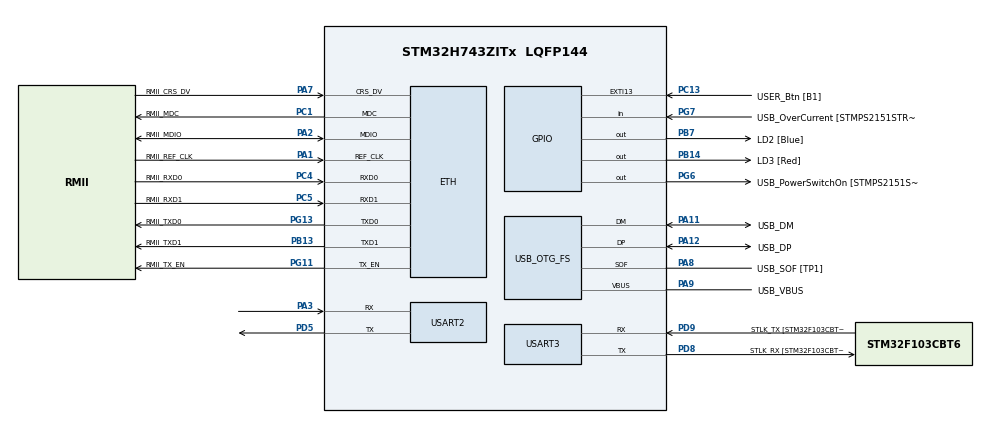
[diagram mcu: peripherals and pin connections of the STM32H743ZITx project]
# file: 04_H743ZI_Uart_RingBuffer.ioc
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ETH.MediaInterface=HAL_ETH_RMII_MODE
Mcu.Family=STM32H7
Mcu.Name=STM32H743ZITx
Mcu.Package=LQFP144
NVIC.PriorityGroup=NVIC_PRIORITYGROUP_4
NVIC.USART2_IRQn=true\:0\:0\:false\:false\:true\:true
PA1.GPIO_Label=RMII_REF_CLK
PA1.Mode=RMII
PA1.Signal=ETH_REF_CLK
PA10.GPIO_Label=USB_ID
PA10.Signal=USB_OTG_FS_ID
PA11.GPIO_Label=USB_DM
PA11.Mode=Device_Only
PA11.Signal=USB_OTG_FS_DM
PA12.GPIO_Label=USB_DP
PA12.Mode=Device_Only
PA12.Signal=USB_OTG_FS_DP
PA13\ (JTMS/SWDIO).GPIO_Label=TMS
PA13\ (JTMS/SWDIO).Mode=Serial_Wire
PA13\ (JTMS/SWDIO).Signal=SYS_JTMS-SWDIO
PA14\ (JTCK/SWCLK).GPIO_Label=TCK
PA14\ (JTCK/SWCLK).Mode=Serial_Wire
PA14\ (JTCK/SWCLK).Signal=SYS_JTCK-SWCLK
PA2.GPIO_Label=RMII_MDIO
PA2.Mode=RMII
PA2.Signal=ETH_MDIO
PA3.Mode=Asynchronous
PA3.Signal=USART2_RX
PA7.GPIO_Label=RMII_CRS_DV
PA7.Mode=RMII
PA7.Signal=ETH_CRS_DV
PA8.GPIO_Label=USB_SOF [TP1]
PA8.Mode=Activate_SOF_FS
PA8.Signal=USB_OTG_FS_SOF
PA9.GPIO_Label=USB_VBUS
PA9.Mode=Activate_VBUS
PA9.Signal=USB_OTG_FS_VBUS
PB13.GPIO_Label=RMII_TXD1
PB13.Mode=RMII
PB13.Signal=ETH_TXD1
PB14.GPIO_Label=LD3 [Red]
PB14.Signal=GPIO_Output
PB3\ (JTDO/TRACESWO).GPIO_Label=SWO
PB3\ (JTDO/TRACESWO).Signal=SYS_JTDO-SWO
PB7.GPIO_Label=LD2 [Blue]
PB7.Signal=GPIO_Output
PC1.GPIO_Label=RMII_MDC
PC1.Mode=RMII
PC1.Signal=ETH_MDC
PC13.GPIO_Label=USER_Btn [B1]
PC13.Signal=GPXTI13
PC14-OSC32_IN\ (OSC32_IN).Mode=LSE-External-Oscillator
PC14-OSC32_IN\ (OSC32_IN).Signal=RCC_OSC32_IN
PC15-OSC32_OUT\ (OSC32_OUT).Mode=LSE-External-Oscillator
PC15-OSC32_OUT\ (OSC32_OUT).Signal=RCC_OSC32_OUT
PC4.GPIO_Label=RMII_RXD0
PC4.Mode=RMII
PC4.Signal=ETH_RXD0
PC5.GPIO_Label=RMII_RXD1
PC5.Mode=RMII
PC5.Signal=ETH_RXD1
PD5.Mode=Asynchronous
PD5.Signal=USART2_TX
PD8.GPIO_Label=STLK_RX [STM32F103CBT6_PA3]
PD8.Mode=Asynchronous
PD8.Signal=USART3_TX
PD9.GPIO_Label=STLK_TX [STM32F103CBT6_PA2]
PD9.Mode=Asynchronous
PD9.Signal=USART3_RX
PG11.GPIO_Label=RMII_TX_EN
PG11.Mode=RMII
PG11.Signal=ETH_TX_EN
PG13.GPIO_Label=RMII_TXD0
PG13.Mode=RMII
PG13.Signal=ETH_TXD0
PG6.GPIO_Label=USB_PowerSwitchOn [STMPS2151STR_EN]
PG6.Signal=GPIO_Output
PG7.GPIO_Label=USB_OverCurrent [STMPS2151STR_FAULT]
PG7.Signal=GPIO_Input
PH0-OSC_IN\ (PH0).GPIO_Label=MCO
PH0-OSC_IN\ (PH0).Mode=HSE-External-Clock-Source
PH0-OSC_IN\ (PH0).Signal=RCC_OSC_IN
PH1-OSC_OUT\ (PH1).Mode=HSE-External-Clock-Source
PH1-OSC_OUT\ (PH1).Signal=RCC_OSC_OUT
ProjectManager.HeapSize=0x200
ProjectManager.StackSize=0x400
ProjectManager.TargetToolchain=EWARM V8
RCC.48MHZClocksFreq_Value=24000000
RCC.ADCFreq_Value=16125000
RCC.AHBFreq_Value=216000000
RCC.APB1CLKDivider=RCC_HCLK_DIV4
RCC.APB1Freq_Value=100000000
RCC.APB1TimFreq_Value=108000000
RCC.APB2CLKDivider=RCC_HCLK_DIV2
RCC.APB2Freq_Value=100000000
RCC.APB2TimFreq_Value=216000000
RCC.APB3Freq_Value=100000000
RCC.APB4Freq_Value=100000000
RCC.CortexFreq_Value=400000000
RCC.D1PPRE=RCC_APB3_DIV2
RCC.D2PPRE1=RCC_APB1_DIV2
RCC.D2PPRE2=RCC_APB2_DIV2
RCC.D3PPRE=RCC_APB4_DIV2
RCC.DIVM1=1
RCC.DIVN1=100
RCC.DIVQ1=4
RCC.HCLKFreq_Value=200000000
RCC.HPRE=RCC_HCLK_DIV2
RCC.HSE_VALUE=8000000
RCC.HSI_VALUE=64000000
RCC.PLLM=25
RCC.PLLMUL=RCC_PLL_MUL9
RCC.PLLN=432
RCC.PLLQ=9
RCC.PLLSourceVirtual=RCC_PLLSOURCE_HSE
RCC.PRESCALERUSB=RCC_USBCLKSOURCE_PLL_DIV1_5
RCC.SYSCLKFreq_VALUE=400000000
RCC.SYSCLKSource=RCC_SYSCLKSOURCE_PLLCLK
RCC.SYSCLKSourceVirtual=RCC_SYSCLKSOURCE_PLLCLK
RCC.USBCLockSelection=RCC_USBCLKSOURCE_HSI48
RCC.USBFreq_Value=48000000
RCC.VCOOutputFreq_Value=432000000
USART2.VirtualMode-Asynchronous=VM_ASYNC
USART3.VirtualMode-Asynchronous=VM_ASYNC
USB_OTG_FS.VirtualMode=Device_Only
board=NUCLEO-H743ZI

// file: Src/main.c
/* USER CODE BEGIN Header */
/**
  ******************************************************************************
  * @file           : main.c
  * @brief          : Main program body
  ******************************************************************************
  ** This notice applies to any and all portions of this file
  * that are not between comment pairs USER CODE BEGIN and
  * USER CODE END. Other portions of this file, whether
  * inserted by the user or by software development tools
  * are owned by their respective copyright owners.
  *
  * COPYRIGHT(c) 2019 STMicroelectronics
  *
  * Redistribution and use in source and binary forms, with or without modification,
  * are permitted provided that the following conditions are met:
  *   1. Redistributions of source code must retain the above copyright notice,
  *      this list of conditions and the following disclaimer.
  *   2. Redistributions in binary form must reproduce the above copyright notice,
  *      this list of conditions and the following disclaimer in the documentation
  *      and/or other materials provided with the distribution.
  *   3. Neither the name of STMicroelectronics nor the names of its contributors
  *      may be used to endorse or promote products derived from this software
  *      without specific prior written permission.
  *
  * THIS SOFTWARE IS PROVIDED BY THE COPYRIGHT HOLDERS AND CONTRIBUTORS "AS IS"
  * AND ANY EXPRESS OR IMPLIED WARRANTIES, INCLUDING, BUT NOT LIMITED TO, THE
  * IMPLIED WARRANTIES OF MERCHANTABILITY AND FITNESS FOR A PARTICULAR PURPOSE ARE
  * DISCLAIMED. IN NO EVENT SHALL THE COPYRIGHT HOLDER OR CONTRIBUTORS BE LIABLE
  * FOR ANY DIRECT, INDIRECT, INCIDENTAL, SPECIAL, EXEMPLARY, OR CONSEQUENTIAL
  * DAMAGES (INCLUDING, BUT NOT LIMITED TO, PROCUREMENT OF SUBSTITUTE GOODS OR
  * SERVICES; LOSS OF USE, DATA, OR PROFITS; OR BUSINESS INTERRUPTION) HOWEVER
  * CAUSED AND ON ANY THEORY OF LIABILITY, WHETHER IN CONTRACT, STRICT LIABILITY,
  * OR TORT (INCLUDING NEGLIGENCE OR OTHERWISE) ARISING IN ANY WAY OUT OF THE USE
  * OF THIS SOFTWARE, EVEN IF ADVISED OF THE POSSIBILITY OF SUCH DAMAGE.
  *
  ******************************************************************************
  */
/* USER CODE END Header */

#include "main.h"
#include "eth.h"
#include "usart.h"
#include "usb_otg.h"
#include "gpio.h"

void SystemClock_Config(void);

int main(void)
{

  /* MCU Configuration--------------------------------------------------------*/

  /* Reset of all peripherals, Initializes the Flash interface and the Systick. */
  HAL_Init();

  /* Configure the system clock */
  SystemClock_Config();

  /* Initialize all configured peripherals */
  MX_GPIO_Init();
  MX_ETH_Init();
  MX_USART3_UART_Init();
  MX_USB_OTG_FS_PCD_Init();
  MX_USART2_UART_Init();

  /* USER CODE BEGIN 2 */
	uart_hal_buffer_init();
	setvbuf( stdout, NULL, _IONBF, 0 );
	printf( "\n\rSTM32F401RE HAL_UART TEST!\n\r" );
	HAL_UART_Receive_IT( &huart2, &uart_hal_rx.dummy, 1 );
  /* USER CODE END 2 */

  /* Infinite loop */
  /* USER CODE BEGIN WHILE */
  uint32_t	tickstart = HAL_GetTick();
  uint32_t	ticknow;
  uint32_t	t = 0;
  while (1)
  {
  	ticknow	= HAL_GetTick();
  	if( ( ticknow - tickstart ) > 100 )
  	{
  		tickstart = ticknow;
  		printf( "Count : %lu \n\r", t++ );
  	}

  	uart_hal_rx_monitor();
    /* USER CODE END WHILE */

  }
}

void SystemClock_Config(void)
{
  RCC_OscInitTypeDef RCC_OscInitStruct = {0};
  RCC_ClkInitTypeDef RCC_ClkInitStruct = {0};
  RCC_PeriphCLKInitTypeDef PeriphClkInitStruct = {0};

  /**Supply configuration update enable
  */
  MODIFY_REG(PWR->CR3, PWR_CR3_SCUEN, 0);
  /**Configure the main internal regulator output voltage
  */
  __HAL_PWR_VOLTAGESCALING_CONFIG(PWR_REGULATOR_VOLTAGE_SCALE1);

  while ((PWR->D3CR & (PWR_D3CR_VOSRDY)) != PWR_D3CR_VOSRDY)
  {

  }
  /**Initializes the CPU, AHB and APB busses clocks
  */
  RCC_OscInitStruct.OscillatorType = RCC_OSCILLATORTYPE_HSI48|RCC_OSCILLATORTYPE_HSE;
  RCC_OscInitStruct.HSEState = RCC_HSE_BYPASS;
  RCC_OscInitStruct.HSI48State = RCC_HSI48_ON;
  RCC_OscInitStruct.PLL.PLLState = RCC_PLL_ON;
  RCC_OscInitStruct.PLL.PLLSource = RCC_PLLSOURCE_HSE;
  RCC_OscInitStruct.PLL.PLLM = 1;
  RCC_OscInitStruct.PLL.PLLN = 100;
  RCC_OscInitStruct.PLL.PLLP = 2;
  RCC_OscInitStruct.PLL.PLLQ = 4;
  RCC_OscInitStruct.PLL.PLLR = 2;
  RCC_OscInitStruct.PLL.PLLRGE = RCC_PLL1VCIRANGE_3;
  RCC_OscInitStruct.PLL.PLLVCOSEL = RCC_PLL1VCOWIDE;
  RCC_OscInitStruct.PLL.PLLFRACN = 0;
  if (HAL_RCC_OscConfig(&RCC_OscInitStruct) != HAL_OK)
  {
    Error_Handler();
  }
  /**Initializes the CPU, AHB and APB busses clocks
  */
  RCC_ClkInitStruct.ClockType = RCC_CLOCKTYPE_HCLK|RCC_CLOCKTYPE_SYSCLK
                              |RCC_CLOCKTYPE_PCLK1|RCC_CLOCKTYPE_PCLK2
                              |RCC_CLOCKTYPE_D3PCLK1|RCC_CLOCKTYPE_D1PCLK1;
  RCC_ClkInitStruct.SYSCLKSource = RCC_SYSCLKSOURCE_PLLCLK;
  RCC_ClkInitStruct.SYSCLKDivider = RCC_SYSCLK_DIV1;
  RCC_ClkInitStruct.AHBCLKDivider = RCC_HCLK_DIV2;
  RCC_ClkInitStruct.APB3CLKDivider = RCC_APB3_DIV2;
  RCC_ClkInitStruct.APB1CLKDivider = RCC_APB1_DIV2;
  RCC_ClkInitStruct.APB2CLKDivider = RCC_APB2_DIV2;
  RCC_ClkInitStruct.APB4CLKDivider = RCC_APB4_DIV2;

  if (HAL_RCC_ClockConfig(&RCC_ClkInitStruct, FLASH_LATENCY_2) != HAL_OK)
  {
    Error_Handler();
  }
  PeriphClkInitStruct.PeriphClockSelection = RCC_PERIPHCLK_USART3|RCC_PERIPHCLK_USART2
                              |RCC_PERIPHCLK_USB;
  PeriphClkInitStruct.Usart234578ClockSelection = RCC_USART234578CLKSOURCE_D2PCLK1;
  PeriphClkInitStruct.UsbClockSelection = RCC_USBCLKSOURCE_HSI48;
  if (HAL_RCCEx_PeriphCLKConfig(&PeriphClkInitStruct) != HAL_OK)
  {
    Error_Handler();
  }
}

void Error_Handler(void)
{
}

/************************ (C) COPYRIGHT STMicroelectronics *****END OF FILE****/
